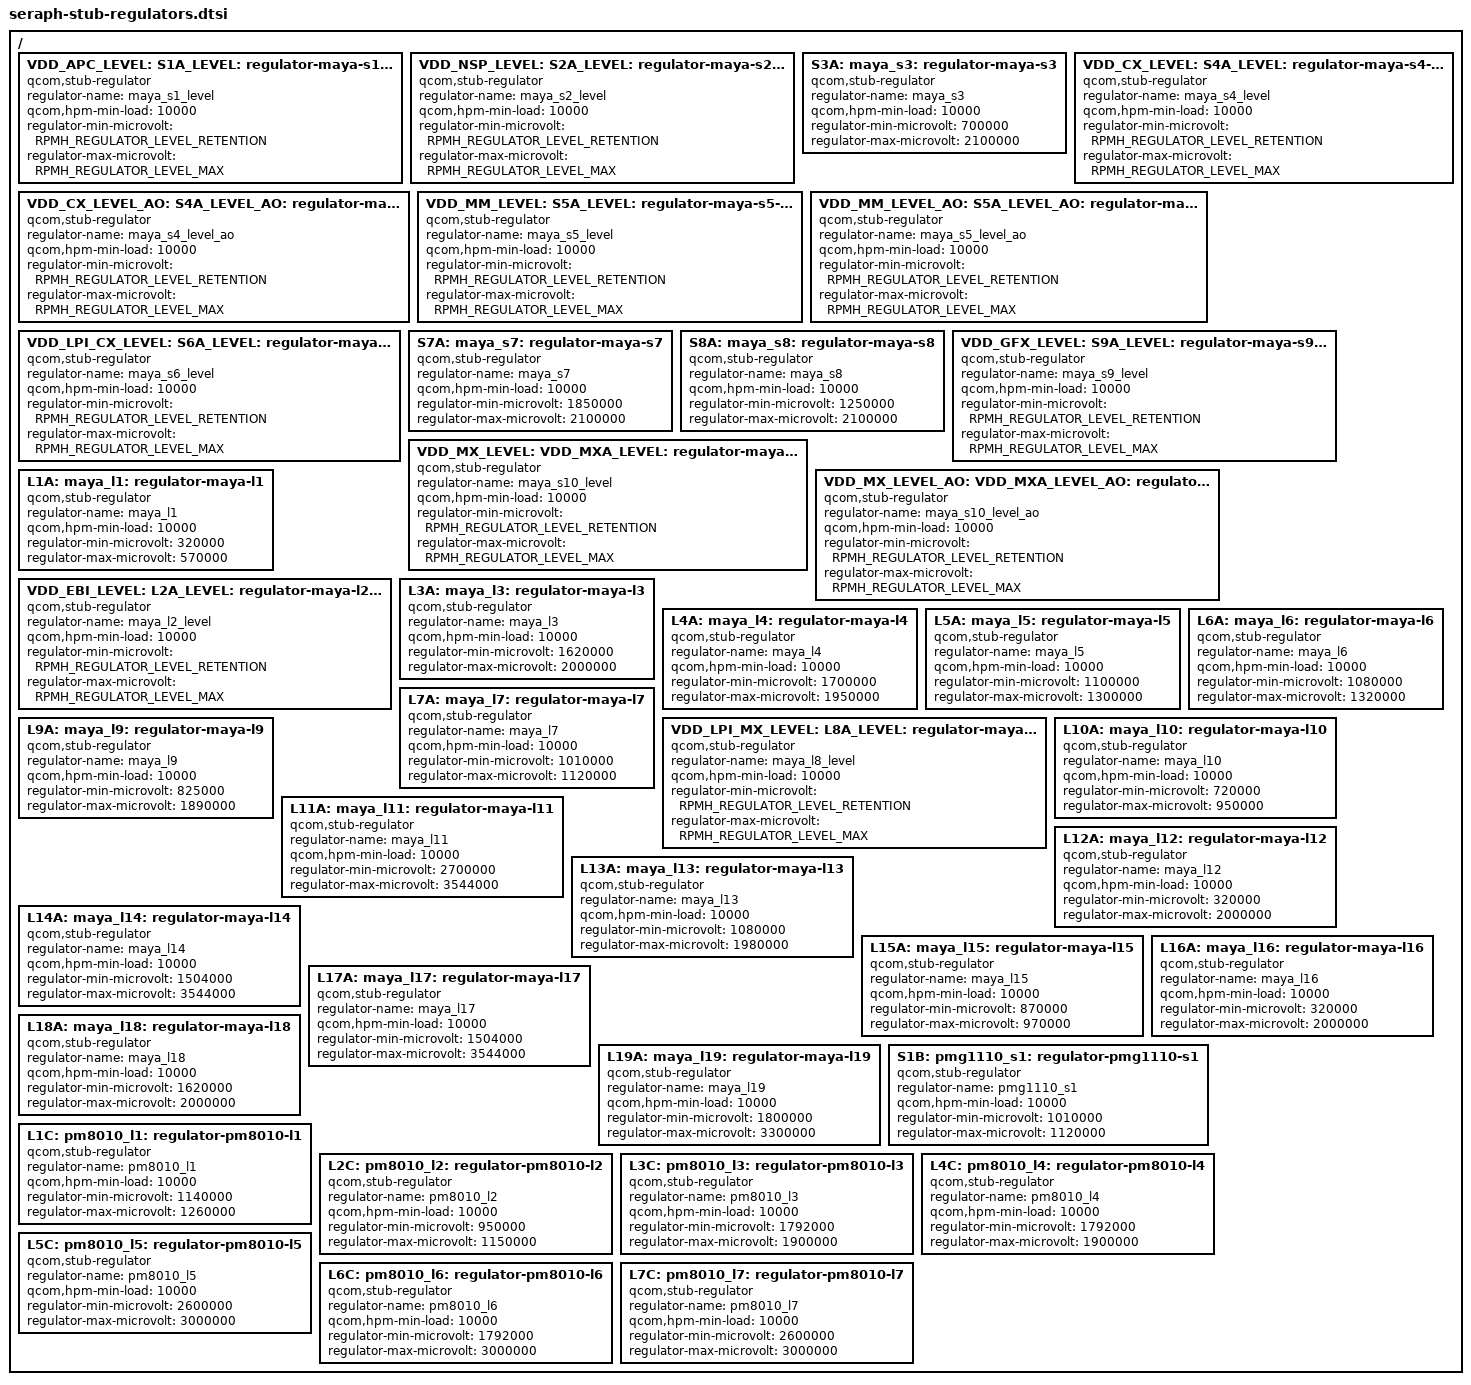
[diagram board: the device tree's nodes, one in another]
#include <dt-bindings/regulator/qcom,rpmh-regulator-levels.h>

/ {
		VDD_APC_LEVEL:
		S1A_LEVEL:
		maya_s1_level: regulator-maya-s1-level {
			compatible = "qcom,stub-regulator";
			regulator-name = "maya_s1_level";
			qcom,hpm-min-load = <10000>;
			regulator-min-microvolt =
				<RPMH_REGULATOR_LEVEL_RETENTION>;
			regulator-max-microvolt = <RPMH_REGULATOR_LEVEL_MAX>;
		};

		VDD_NSP_LEVEL:
		S2A_LEVEL:
		maya_s2_level: regulator-maya-s2-level {
			compatible = "qcom,stub-regulator";
			regulator-name = "maya_s2_level";
			qcom,hpm-min-load = <10000>;
			regulator-min-microvolt =
				<RPMH_REGULATOR_LEVEL_RETENTION>;
			regulator-max-microvolt = <RPMH_REGULATOR_LEVEL_MAX>;
		};

		S3A:
		maya_s3: regulator-maya-s3 {
			compatible = "qcom,stub-regulator";
			regulator-name = "maya_s3";
			qcom,hpm-min-load = <10000>;
			regulator-min-microvolt = <700000>;
			regulator-max-microvolt = <2100000>;
		};

		VDD_CX_LEVEL:
		S4A_LEVEL:
		maya_s4_level: regulator-maya-s4-level {
			compatible = "qcom,stub-regulator";
			regulator-name = "maya_s4_level";
			qcom,hpm-min-load = <10000>;
			regulator-min-microvolt =
				<RPMH_REGULATOR_LEVEL_RETENTION>;
			regulator-max-microvolt = <RPMH_REGULATOR_LEVEL_MAX>;
		};

		VDD_CX_LEVEL_AO:
		S4A_LEVEL_AO:
		maya_s4_level_ao: regulator-maya-s4-level-ao {
			compatible = "qcom,stub-regulator";
			regulator-name = "maya_s4_level_ao";
			qcom,hpm-min-load = <10000>;
			regulator-min-microvolt =
				<RPMH_REGULATOR_LEVEL_RETENTION>;
			regulator-max-microvolt = <RPMH_REGULATOR_LEVEL_MAX>;
		};

		VDD_MM_LEVEL:
		S5A_LEVEL:
		maya_s5_level: regulator-maya-s5-level {
			compatible = "qcom,stub-regulator";
			regulator-name = "maya_s5_level";
			qcom,hpm-min-load = <10000>;
			regulator-min-microvolt =
				<RPMH_REGULATOR_LEVEL_RETENTION>;
			regulator-max-microvolt = <RPMH_REGULATOR_LEVEL_MAX>;
		};

		VDD_MM_LEVEL_AO:
		S5A_LEVEL_AO:
		maya_s5_level_ao: regulator-maya-s5-level-ao {
			compatible = "qcom,stub-regulator";
			regulator-name = "maya_s5_level_ao";
			qcom,hpm-min-load = <10000>;
			regulator-min-microvolt =
				<RPMH_REGULATOR_LEVEL_RETENTION>;
			regulator-max-microvolt = <RPMH_REGULATOR_LEVEL_MAX>;
		};

		VDD_LPI_CX_LEVEL:
		S6A_LEVEL:
		maya_s6_level: regulator-maya-s6-level {
			compatible = "qcom,stub-regulator";
			regulator-name = "maya_s6_level";
			qcom,hpm-min-load = <10000>;
			regulator-min-microvolt =
				<RPMH_REGULATOR_LEVEL_RETENTION>;
			regulator-max-microvolt = <RPMH_REGULATOR_LEVEL_MAX>;
		};

		S7A:
		maya_s7: regulator-maya-s7 {
			compatible = "qcom,stub-regulator";
			regulator-name = "maya_s7";
			qcom,hpm-min-load = <10000>;
			regulator-min-microvolt = <1850000>;
			regulator-max-microvolt = <2100000>;
		};

		S8A:
		maya_s8: regulator-maya-s8 {
			compatible = "qcom,stub-regulator";
			regulator-name = "maya_s8";
			qcom,hpm-min-load = <10000>;
			regulator-min-microvolt = <1250000>;
			regulator-max-microvolt = <2100000>;
		};

		VDD_GFX_LEVEL:
		S9A_LEVEL:
		maya_s9_level: regulator-maya-s9-level {
			compatible = "qcom,stub-regulator";
			regulator-name = "maya_s9_level";
			qcom,hpm-min-load = <10000>;
			regulator-min-microvolt =
				<RPMH_REGULATOR_LEVEL_RETENTION>;
			regulator-max-microvolt = <RPMH_REGULATOR_LEVEL_MAX>;
		};

		VDD_MX_LEVEL:
		VDD_MXA_LEVEL:
		S10A_LEVEL:
		maya_s10_level: regulator-maya-s10-level {
			compatible = "qcom,stub-regulator";
			regulator-name = "maya_s10_level";
			qcom,hpm-min-load = <10000>;
			regulator-min-microvolt =
				<RPMH_REGULATOR_LEVEL_RETENTION>;
			regulator-max-microvolt = <RPMH_REGULATOR_LEVEL_MAX>;
		};

		VDD_MX_LEVEL_AO:
		VDD_MXA_LEVEL_AO:
		S10A_LEVEL_AO:
		maya_s10_level_ao: regulator-maya-s10-level-ao {
			compatible = "qcom,stub-regulator";
			regulator-name = "maya_s10_level_ao";
			qcom,hpm-min-load = <10000>;
			regulator-min-microvolt =
				<RPMH_REGULATOR_LEVEL_RETENTION>;
			regulator-max-microvolt = <RPMH_REGULATOR_LEVEL_MAX>;
		};

		L1A:
		maya_l1: regulator-maya-l1 {
			compatible = "qcom,stub-regulator";
			regulator-name = "maya_l1";
			qcom,hpm-min-load = <10000>;
			regulator-min-microvolt = <320000>;
			regulator-max-microvolt = <570000>;
		};

		VDD_EBI_LEVEL:
		L2A_LEVEL:
		maya_l2_level: regulator-maya-l2-level {
			compatible = "qcom,stub-regulator";
			regulator-name = "maya_l2_level";
			qcom,hpm-min-load = <10000>;
			regulator-min-microvolt =
				<RPMH_REGULATOR_LEVEL_RETENTION>;
			regulator-max-microvolt = <RPMH_REGULATOR_LEVEL_MAX>;
		};

		L3A:
		maya_l3: regulator-maya-l3 {
			compatible = "qcom,stub-regulator";
			regulator-name = "maya_l3";
			qcom,hpm-min-load = <10000>;
			regulator-min-microvolt = <1620000>;
			regulator-max-microvolt = <2000000>;
		};

		L4A:
		maya_l4: regulator-maya-l4 {
			compatible = "qcom,stub-regulator";
			regulator-name = "maya_l4";
			qcom,hpm-min-load = <10000>;
			regulator-min-microvolt = <1700000>;
			regulator-max-microvolt = <1950000>;
		};

		L5A:
		maya_l5: regulator-maya-l5 {
			compatible = "qcom,stub-regulator";
			regulator-name = "maya_l5";
			qcom,hpm-min-load = <10000>;
			regulator-min-microvolt = <1100000>;
			regulator-max-microvolt = <1300000>;
		};

		L6A:
		maya_l6: regulator-maya-l6 {
			compatible = "qcom,stub-regulator";
			regulator-name = "maya_l6";
			qcom,hpm-min-load = <10000>;
			regulator-min-microvolt = <1080000>;
			regulator-max-microvolt = <1320000>;
		};

		L7A:
		maya_l7: regulator-maya-l7 {
			compatible = "qcom,stub-regulator";
			regulator-name = "maya_l7";
			qcom,hpm-min-load = <10000>;
			regulator-min-microvolt = <1010000>;
			regulator-max-microvolt = <1120000>;
		};

		VDD_LPI_MX_LEVEL:
		L8A_LEVEL:
		maya_l8_level: regulator-maya-l8-level {
			compatible = "qcom,stub-regulator";
			regulator-name = "maya_l8_level";
			qcom,hpm-min-load = <10000>;
			regulator-min-microvolt =
				<RPMH_REGULATOR_LEVEL_RETENTION>;
			regulator-max-microvolt = <RPMH_REGULATOR_LEVEL_MAX>;
		};

		L9A:
		maya_l9: regulator-maya-l9 {
			compatible = "qcom,stub-regulator";
			regulator-name = "maya_l9";
			qcom,hpm-min-load = <10000>;
			regulator-min-microvolt = <825000>;
			regulator-max-microvolt = <1890000>;
		};

		L10A:
		maya_l10: regulator-maya-l10 {
			compatible = "qcom,stub-regulator";
			regulator-name = "maya_l10";
			qcom,hpm-min-load = <10000>;
			regulator-min-microvolt = <720000>;
			regulator-max-microvolt = <950000>;
		};

		L11A:
		maya_l11: regulator-maya-l11 {
			compatible = "qcom,stub-regulator";
			regulator-name = "maya_l11";
			qcom,hpm-min-load = <10000>;
			regulator-min-microvolt = <2700000>;
			regulator-max-microvolt = <3544000>;
		};

		L12A:
		maya_l12: regulator-maya-l12 {
			compatible = "qcom,stub-regulator";
			regulator-name = "maya_l12";
			qcom,hpm-min-load = <10000>;
			regulator-min-microvolt = <320000>;
			regulator-max-microvolt = <2000000>;
		};

		L13A:
		maya_l13: regulator-maya-l13 {
			compatible = "qcom,stub-regulator";
			regulator-name = "maya_l13";
			qcom,hpm-min-load = <10000>;
			regulator-min-microvolt = <1080000>;
			regulator-max-microvolt = <1980000>;
		};

		L14A:
		maya_l14: regulator-maya-l14 {
			compatible = "qcom,stub-regulator";
			regulator-name = "maya_l14";
			qcom,hpm-min-load = <10000>;
			regulator-min-microvolt = <1504000>;
			regulator-max-microvolt = <3544000>;
		};

		L15A:
		maya_l15: regulator-maya-l15 {
			compatible = "qcom,stub-regulator";
			regulator-name = "maya_l15";
			qcom,hpm-min-load = <10000>;
			regulator-min-microvolt = <870000>;
			regulator-max-microvolt = <970000>;
		};

		L16A:
		maya_l16: regulator-maya-l16 {
			compatible = "qcom,stub-regulator";
			regulator-name = "maya_l16";
			qcom,hpm-min-load = <10000>;
			regulator-min-microvolt = <320000>;
			regulator-max-microvolt = <2000000>;
		};

		L17A:
		maya_l17: regulator-maya-l17 {
			compatible = "qcom,stub-regulator";
			regulator-name = "maya_l17";
			qcom,hpm-min-load = <10000>;
			regulator-min-microvolt = <1504000>;
			regulator-max-microvolt = <3544000>;
		};

		L18A:
		maya_l18: regulator-maya-l18 {
			compatible = "qcom,stub-regulator";
			regulator-name = "maya_l18";
			qcom,hpm-min-load = <10000>;
			regulator-min-microvolt = <1620000>;
			regulator-max-microvolt = <2000000>;
		};

		L19A:
		maya_l19: regulator-maya-l19 {
			compatible = "qcom,stub-regulator";
			regulator-name = "maya_l19";
			qcom,hpm-min-load = <10000>;
			regulator-min-microvolt = <1800000>;
			regulator-max-microvolt = <3300000>;
		};

		S1B:
		pmg1110_s1: regulator-pmg1110-s1 {
			compatible = "qcom,stub-regulator";
			regulator-name = "pmg1110_s1";
			qcom,hpm-min-load = <10000>;
			regulator-min-microvolt = <1010000>;
			regulator-max-microvolt = <1120000>;
		};

		L1C:
		pm8010_l1: regulator-pm8010-l1 {
			compatible = "qcom,stub-regulator";
			regulator-name = "pm8010_l1";
			qcom,hpm-min-load = <10000>;
			regulator-min-microvolt = <1140000>;
			regulator-max-microvolt = <1260000>;
		};

		L2C:
		pm8010_l2: regulator-pm8010-l2 {
			compatible = "qcom,stub-regulator";
			regulator-name = "pm8010_l2";
			qcom,hpm-min-load = <10000>;
			regulator-min-microvolt = <950000>;
			regulator-max-microvolt = <1150000>;
		};

		L3C:
		pm8010_l3: regulator-pm8010-l3 {
			compatible = "qcom,stub-regulator";
			regulator-name = "pm8010_l3";
			qcom,hpm-min-load = <10000>;
			regulator-min-microvolt = <1792000>;
			regulator-max-microvolt = <1900000>;
		};

		L4C:
		pm8010_l4: regulator-pm8010-l4 {
			compatible = "qcom,stub-regulator";
			regulator-name = "pm8010_l4";
			qcom,hpm-min-load = <10000>;
			regulator-min-microvolt = <1792000>;
			regulator-max-microvolt = <1900000>;
		};

		L5C:
		pm8010_l5: regulator-pm8010-l5 {
			compatible = "qcom,stub-regulator";
			regulator-name = "pm8010_l5";
			qcom,hpm-min-load = <10000>;
			regulator-min-microvolt = <2600000>;
			regulator-max-microvolt = <3000000>;
		};

		L6C:
		pm8010_l6: regulator-pm8010-l6 {
			compatible = "qcom,stub-regulator";
			regulator-name = "pm8010_l6";
			qcom,hpm-min-load = <10000>;
			regulator-min-microvolt = <1792000>;
			regulator-max-microvolt = <3000000>;
		};

		L7C:
		pm8010_l7: regulator-pm8010-l7 {
			compatible = "qcom,stub-regulator";
			regulator-name = "pm8010_l7";
			qcom,hpm-min-load = <10000>;
			regulator-min-microvolt = <2600000>;
			regulator-max-microvolt = <3000000>;
		};
};
